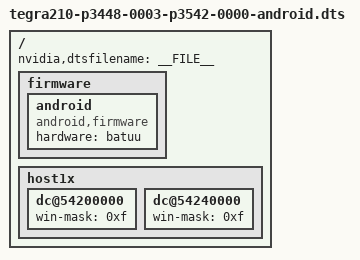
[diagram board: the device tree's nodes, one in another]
#include "tegra210-p3448-0003-p3542-0000.dts"

/ {
	nvidia,dtsfilename = __FILE__;

	firmware {
		android {
			compatible = "android,firmware";
			hardware = "batuu";
		};
	};

	host1x {
		dc@54200000 {
			win-mask = <0xf>;
		};

		dc@54240000 {
			win-mask = <0xf>;
		};
	};
};
